# STM32G474xx register map
File version: 1.6
CPU: CM4 r0p1, little endian, MPU, FPU, 4 interrupt priority bits
Registers are 32-bit, read-write, reset 0x0 unless marked. A register's access mark holds for its fields unless they carry their own. Offsets are from the block's base; [hi:lo] are bit positions; {n}, {i} and the like mark numbered series.

## HRTIM_Master — High Resolution Timer: Master Timers
Base 0x40016800
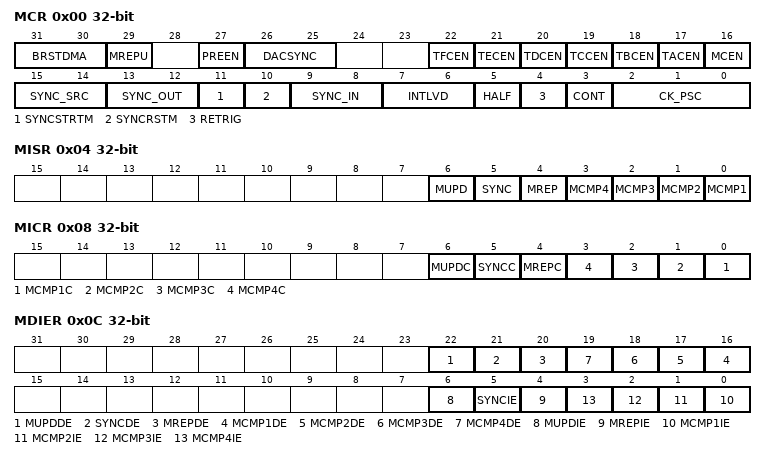
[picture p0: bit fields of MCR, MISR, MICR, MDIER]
0x00 MCR — Master Timer Control Register
  [31:30] BRSTDMA — Burst DMA Update
  [29] MREPU — Master Timer Repetition update
  [27] PREEN — Preload enable
  [26:25] DACSYNC — AC Synchronization
  [22] TFCEN — Timer F counter enable
  [21] TECEN — Timer E counter enable
  [20] TDCEN — Timer D counter enable
  [19] TCCEN — Timer C counter enable
  [18] TBCEN — Timer B counter enable
  [17] TACEN — Timer A counter enable
  [16] MCEN — Master Counter enable
  [15:14] SYNC_SRC — Synchronization source
  [13:12] SYNC_OUT — Synchronization output
  [11] SYNCSTRTM — Synchronization Starts Master
  [10] SYNCRSTM — Synchronization Resets Master
  [9:8] SYNC_IN — synchronization input
  [7:6] INTLVD — Interleaved mode
  [5] HALF — Half mode enable
  [4] RETRIG — Master Re-triggerable mode
  [3] CONT — Master Continuous mode
  [2:0] CK_PSC — HRTIM Master Clock prescaler
0x04 MISR ro — Master Timer Interrupt Status Register
  [6] MUPD — Master Update Interrupt Flag
  [5] SYNC — Sync Input Interrupt Flag
  [4] MREP — Master Repetition Interrupt Flag
  [n-1] MCMP{n} (n=1..4) — Master Compare {n} Interrupt Flag
0x08 MICR wo — Master Timer Interrupt Clear Register
  [6] MUPDC — Master update Interrupt flag clear
  [5] SYNCC — Sync Input Interrupt flag clear
  [4] MREPC — Repetition Interrupt flag clear
  [n-1] MCMP{n}C (n=1..4) — Master Compare {n} Interrupt flag clear
0x0C MDIER — HRTIM Master Timer DMA / Interrupt Enable Register
  [22] MUPDDE, [21] SYNCDE, [20] MREPDE, [n+15] MCMP{n}DE (n=1..4), [6] MUPDIE, [5] SYNCIE, [4] MREPIE, [n-1] MCMP{n}IE (n=1..4)
0x10 MCNTR — Master Timer Counter Register
  [15:0] MCNT — Counter value
0x14 MPER reset 0xFFFF — Master Timer Period Register
  [15:0] MPER — Master Timer Period value
0x18 MREP — Master Timer Repetition Register
  [7:0] MREP — Master Timer Repetition counter value
0x1C MCMP1R — Master Timer Compare 1 Register
  [15:0] MCMP1 — Master Timer Compare 1 value
{0x1C+4i} MCMP{i}R (i=2..4) — Master Timer Compare {i} Register
  [15:0] MCMP{i} — Master Timer Compare {i} value

## QUADSPI — QuadSPI interface
Base 0xA0001000
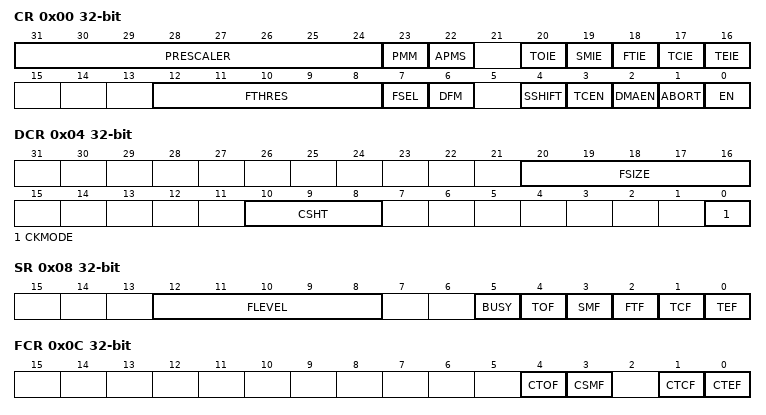
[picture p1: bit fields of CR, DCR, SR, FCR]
0x00 CR — control register
  [31:24] PRESCALER — Clock prescaler
  [23] PMM — Polling match mode
  [22] APMS — Automatic poll mode stop
  [20] TOIE — TimeOut interrupt enable
  [19] SMIE — Status match interrupt enable
  [18] FTIE — FIFO threshold interrupt enable
  [17] TCIE — Transfer complete interrupt enable
  [16] TEIE — Transfer error interrupt enable
  [12:8] FTHRES — IFO threshold level
  [7] FSEL
  [6] DFM
  [4] SSHIFT — Sample shift
  [3] TCEN — Timeout counter enable
  [2] DMAEN — DMA enable
  [1] ABORT — Abort request
  [0] EN — Enable
0x04 DCR — device configuration register
  [20:16] FSIZE — FLASH memory size
  [10:8] CSHT — Chip select high time
  [0] CKMODE — Mode 0 / mode 3
0x08 SR ro — status register
  [12:8] FLEVEL — FIFO level
  [5] BUSY
  [4] TOF — Timeout flag
  [3] SMF — Status match flag
  [2] FTF — FIFO threshold flag
  [1] TCF — Transfer complete flag
  [0] TEF — Transfer error flag
0x0C FCR — flag clear register
  [4] CTOF — Clear timeout flag
  [3] CSMF — Clear status match flag
  [1] CTCF — Clear transfer complete flag
  [0] CTEF — Clear transfer error flag
0x10 DLR — data length register
  [31:0] DL — Data length
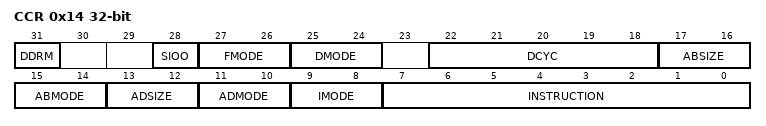
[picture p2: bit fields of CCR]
0x14 CCR — communication configuration register
  [31] DDRM — Double data rate mode
  [28] SIOO — Send instruction only once mode
  [27:26] FMODE — Functional mode
  [25:24] DMODE — Data mode
  [22:18] DCYC — Number of dummy cycles
  [17:16] ABSIZE — Alternate bytes size
  [15:14] ABMODE — Alternate bytes mode
  [13:12] ADSIZE — Address size
  [11:10] ADMODE — Address mode
  [9:8] IMODE — Instruction mode
  [7:0] INSTRUCTION
0x18 AR — address register
  [31:0] ADDRESS
0x1C ABR
  [31:0] ALTERNATE
0x20 DR — data register
  [31:0] DATA
0x24 PSMKR — polling status mask register
  [31:0] MASK — Status mask
0x28 PSMAR — polling status match register
  [31:0] MATCH — Status match
0x2C PIR — polling interval register
  [15:0] INTERVAL — Polling interval
0x30 LPTR — low-power timeout register
  [15:0] TIMEOUT — Timeout period
